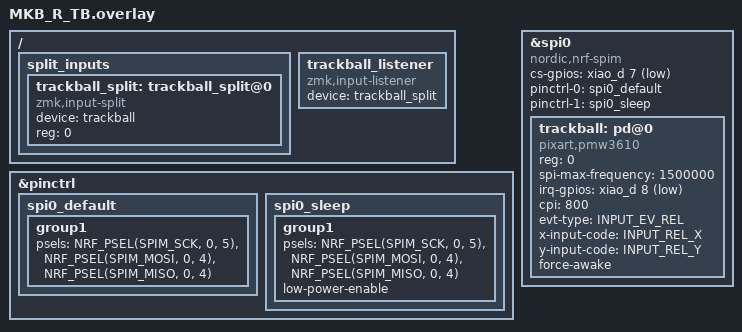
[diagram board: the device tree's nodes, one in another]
#include "MKB_R_Base.dtsi"

&pinctrl {
    spi0_default: spi0_default {
        group1 {
            psels = <NRF_PSEL(SPIM_SCK, 0, 5)>,
                    <NRF_PSEL(SPIM_MOSI, 0, 4)>,
                    <NRF_PSEL(SPIM_MISO, 0, 4)>;
        };
    };

    spi0_sleep: spi0_sleep {
        group1 {
            psels = <NRF_PSEL(SPIM_SCK, 0, 5)>,
                    <NRF_PSEL(SPIM_MOSI, 0, 4)>,
                    <NRF_PSEL(SPIM_MISO, 0, 4)>;
            low-power-enable;
        };
    };
};

&spi0 {
    status = "okay";
    cs-gpios =  <&xiao_d 7 GPIO_ACTIVE_LOW>;
    pinctrl-0 = <&spi0_default>;
    pinctrl-1 = <&spi0_sleep>;
    pinctrl-names = "default", "sleep";
    compatible = "nordic,nrf-spim";

    trackball: pd@0 {
        status = "okay";
        compatible = "pixart,pmw3610";
        reg = <0>;
        spi-max-frequency = <1500000>;
        irq-gpios = <&xiao_d 8 (GPIO_ACTIVE_LOW | GPIO_PULL_UP)>;
        cpi = <800>;
        evt-type = <INPUT_EV_REL>;
        x-input-code = <INPUT_REL_X>;
        y-input-code = <INPUT_REL_Y>;
        force-awake;
    };
};

/*input-split*/
/ {
    split_inputs {
        #address-cells = <1>;
        #size-cells = <0>;

        trackball_split: trackball_split@0 {
            compatible = "zmk,input-split";
            status = "okay";
            device = <&trackball>;
            reg = <0>;
        };
    };

    trackball_listener: trackball_listener {
        compatible = "zmk,input-listener";
        status = "okay";
        device = <&trackball_split>;
    };
};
